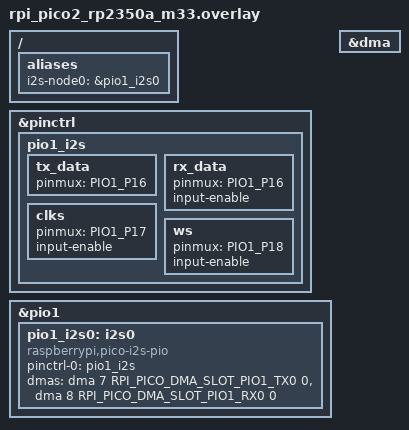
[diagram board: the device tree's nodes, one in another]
#include <dt-bindings/pinctrl/rpi-pico-rp2350a-pinctrl.h>
#include <zephyr/dt-bindings/dma/rpi-pico-dma-rp2350.h>

/ {
	aliases {
		i2s-node0 = &pio1_i2s0;
	};
};

/*
 * Single-device loopback: tx_data and rx_data are the same pin, so the loopback
 * happens on the pad and this configuration needs no external wiring at all.
 *
 * The pins are deliberately kept clear of GP7..GP12, which the two-device
 * variant (rpi_pico2_rp2350a_m33_two_dev.overlay) uses and jumpers together.
 * Leaving those jumpers fitted must not perturb this test: they would otherwise
 * hang a wire and a second pad off every signal here, and GP8 in particular is
 * both driven and sampled within a fraction of a bit-clock period.
 *
 * BCLK must be rx_data + 1: rx_target reads data at in_base+0 and the bit clock
 * at in_base+1 (i2s_rpi_pico_pio.c:413-414).
 */
&pinctrl {
	pio1_i2s: pio1_i2s {
		tx_data: tx_data {
			pinmux = <PIO1_P16>;
		};
		rx_data: rx_data {
			pinmux = <PIO1_P16>;
			/* Enable the pad input buffer so the PIO `in pins` can sample
			 * the RX data line (off by default).
			 */
			input-enable;
		};
		clks: clks {
			pinmux = <PIO1_P17>;
			input-enable;
		};
		ws: ws {
			pinmux = <PIO1_P18>;
			input-enable;
		};
	};
};

&pio1 {
	status = "okay";

	pio1_i2s0: i2s0 {
		compatible = "raspberrypi,pico-i2s-pio";
		status = "okay";

		pinctrl-0 = <&pio1_i2s>;
		pinctrl-names = "default";

		#address-cells = <1>;
		#size-cells = <0>;

		dmas = <&dma 7 RPI_PICO_DMA_SLOT_PIO1_TX0 0>,
		       <&dma 8 RPI_PICO_DMA_SLOT_PIO1_RX0 0>;
		dma-names = "tx", "rx";
	};
};

&dma {
	status = "okay";
};
